# STM32L476 register map
File version: 1.0
CPU: CM4 r0p1, little endian, MPU, FPU, 4 interrupt priority bits
Registers are 32-bit, read-write, reset 0x0 unless marked. A register's access mark holds for its fields unless they carry their own. Offsets are from the block's base; [hi:lo] are bit positions; {n}, {i} and the like mark numbered series.

## NVIC — Nested Vectored Interrupt Controller
Base 0xE000E100
{0x0+4i} ISER{i} (i=0..2) — Interrupt Set-Enable Register
  [31:0] SETENA
{0x80+4i} ICER{i} (i=0..2) — Interrupt Clear-Enable Register
  [31:0] CLRENA
{0x100+4i} ISPR{i} (i=0..2) — Interrupt Set-Pending Register
  [31:0] SETPEND
{0x180+4i} ICPR{i} (i=0..2) — Interrupt Clear-Pending Register
  [31:0] CLRPEND
{0x200+4i} IABR{i} ro (i=0..2) — Interrupt Active Bit Register
  [31:0] ACTIVE
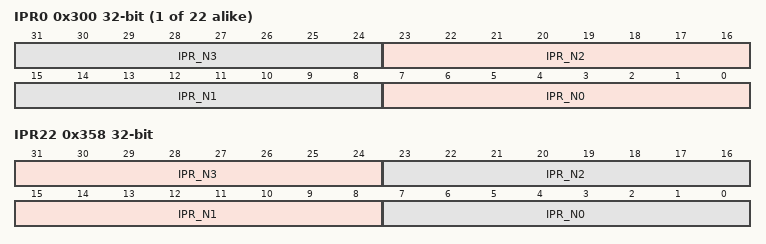
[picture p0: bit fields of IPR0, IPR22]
{0x300+4i} IPR{i} (i=0..21) — Interrupt Priority Register
  [8n+7:8n] IPR_N{n} (n=0..3)
0x358 IPR22 — Interrupt Priority Register
  [31:24] IPR_N3
  [23:16] IPR_N2 — IPR_N0
  [15:8] IPR_N1
  [7:0] IPR_N0

## CRS — Clock recovery system
Base 0x40006000
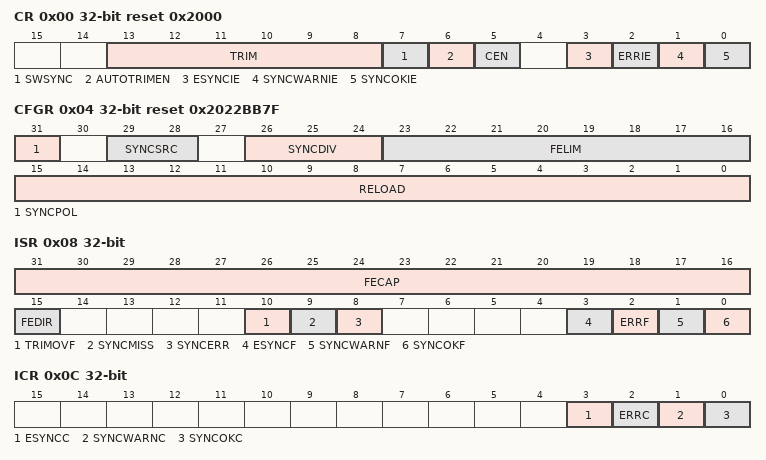
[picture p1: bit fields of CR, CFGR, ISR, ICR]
0x00 CR reset 0x2000 — control register
  [13:8] TRIM — HSI48 oscillator smooth trimming
  [7] SWSYNC — Generate software SYNC event
  [6] AUTOTRIMEN — Automatic trimming enable
  [5] CEN — Frequency error counter enable
  [3] ESYNCIE — Expected SYNC interrupt enable
  [2] ERRIE — Synchronization or trimming error interrupt enable
  [1] SYNCWARNIE — SYNC warning interrupt enable
  [0] SYNCOKIE — SYNC event OK interrupt enable
0x04 CFGR reset 0x2022BB7F — configuration register
  [31] SYNCPOL — SYNC polarity selection
  [29:28] SYNCSRC — SYNC signal source selection
  [26:24] SYNCDIV — SYNC divider
  [23:16] FELIM — Frequency error limit
  [15:0] RELOAD — Counter reload value
0x08 ISR ro — interrupt and status register
  [31:16] FECAP — Frequency error capture
  [15] FEDIR — Frequency error direction
  [10] TRIMOVF — Trimming overflow or underflow
  [9] SYNCMISS — SYNC missed
  [8] SYNCERR — SYNC error
  [3] ESYNCF — Expected SYNC flag
  [2] ERRF — Error flag
  [1] SYNCWARNF — SYNC warning flag
  [0] SYNCOKF — SYNC event OK flag
0x0C ICR — interrupt flag clear register
  [3] ESYNCC — Expected SYNC clear flag
  [2] ERRC — Error clear flag
  [1] SYNCWARNC — SYNC warning clear flag
  [0] SYNCOKC — SYNC event OK clear flag

## DCMI — Digital camera interface
Base 0x50050000
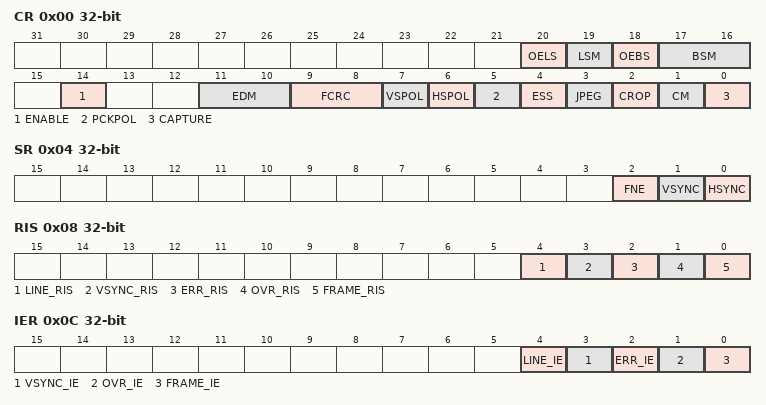
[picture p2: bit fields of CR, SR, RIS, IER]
0x00 CR — control register 1
  [20] OELS — Odd/Even Line Select (Line Select Start)
  [19] LSM — Line Select mode
  [18] OEBS — Odd/Even Byte Select (Byte Select Start)
  [17:16] BSM — Byte Select mode
  [14] ENABLE — DCMI enable
  [11:10] EDM — Extended data mode
  [9:8] FCRC — Frame capture rate control
  [7] VSPOL — Vertical synchronization polarity
  [6] HSPOL — Horizontal synchronization polarity
  [5] PCKPOL — Pixel clock polarity
  [4] ESS — Embedded synchronization select
  [3] JPEG — JPEG format
  [2] CROP — Crop feature
  [1] CM — Capture mode
  [0] CAPTURE — Capture enable
0x04 SR ro — status register
  [2] FNE — FIFO not empty
  [1] VSYNC
  [0] HSYNC
0x08 RIS ro — raw interrupt status register
  [4] LINE_RIS — Line raw interrupt status
  [3] VSYNC_RIS — VSYNC raw interrupt status
  [2] ERR_RIS — Synchronization error raw interrupt status
  [1] OVR_RIS — Overrun raw interrupt status
  [0] FRAME_RIS — Capture complete raw interrupt status
0x0C IER — interrupt enable register
  [4] LINE_IE — Line interrupt enable
  [3] VSYNC_IE — VSYNC interrupt enable
  [2] ERR_IE — Synchronization error interrupt enable
  [1] OVR_IE — Overrun interrupt enable
  [0] FRAME_IE — Capture complete interrupt enable
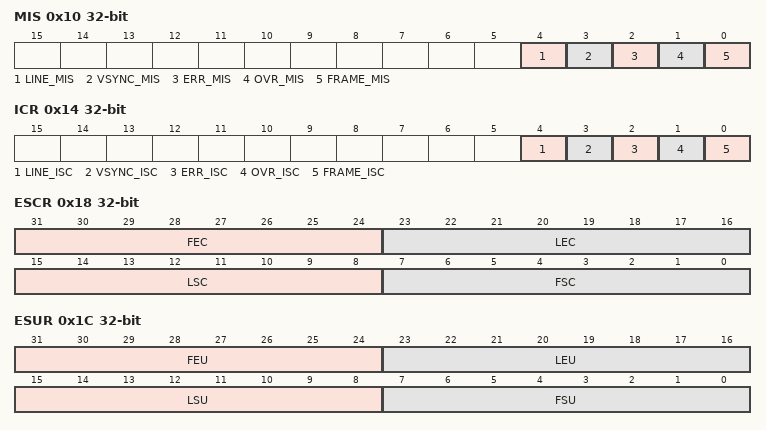
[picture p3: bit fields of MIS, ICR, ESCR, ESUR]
0x10 MIS ro — masked interrupt status register
  [4] LINE_MIS — Line masked interrupt status
  [3] VSYNC_MIS — VSYNC masked interrupt status
  [2] ERR_MIS — Synchronization error masked interrupt status
  [1] OVR_MIS — Overrun masked interrupt status
  [0] FRAME_MIS — Capture complete masked interrupt status
0x14 ICR wo — interrupt clear register
  [4] LINE_ISC — line interrupt status clear
  [3] VSYNC_ISC — Vertical synch interrupt status clear
  [2] ERR_ISC — Synchronization error interrupt status clear
  [1] OVR_ISC — Overrun interrupt status clear
  [0] FRAME_ISC — Capture complete interrupt status clear
0x18 ESCR — embedded synchronization code register
  [31:24] FEC — Frame end delimiter code
  [23:16] LEC — Line end delimiter code
  [15:8] LSC — Line start delimiter code
  [7:0] FSC — Frame start delimiter code
0x1C ESUR — embedded synchronization unmask register
  [31:24] FEU — Frame end delimiter unmask
  [23:16] LEU — Line end delimiter unmask
  [15:8] LSU — Line start delimiter unmask
  [7:0] FSU — Frame start delimiter unmask
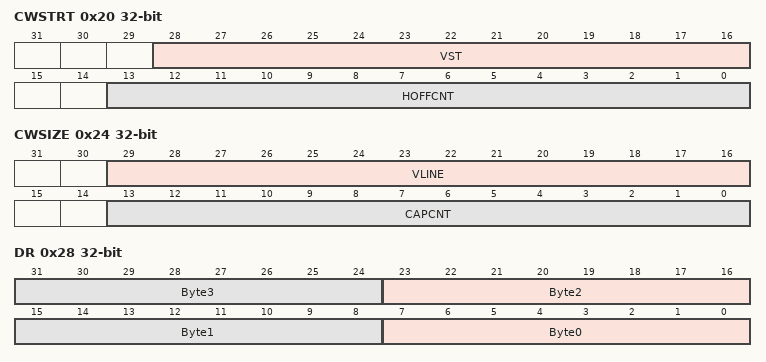
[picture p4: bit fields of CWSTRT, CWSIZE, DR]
0x20 CWSTRT — crop window start
  [28:16] VST — Vertical start line count
  [13:0] HOFFCNT — Horizontal offset count
0x24 CWSIZE — crop window size
  [29:16] VLINE — Vertical line count
  [13:0] CAPCNT — Capture count
0x28 DR ro — data register
  [8n+7:8n] Byte{n} (n=0..3) — Data byte {n}

## FPU — Floting point unit
Base 0xE000EF34
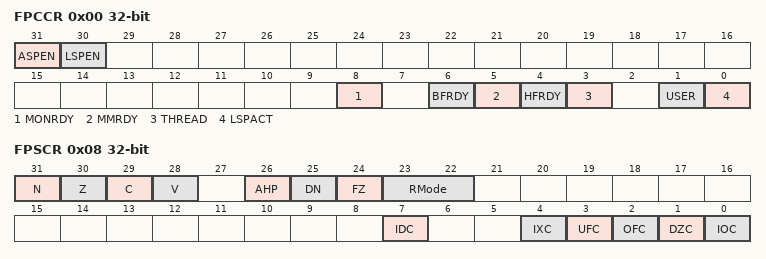
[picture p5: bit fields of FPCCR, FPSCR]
0x00 FPCCR — Floating-point context control register
  [31] ASPEN, [30] LSPEN, [8] MONRDY, [6] BFRDY, [5] MMRDY, [4] HFRDY, [3] THREAD, [1] USER, [0] LSPACT
0x04 FPCAR — Floating-point context address register
  [31:3] ADDRESS — Location of unpopulated floating-point
0x08 FPSCR — Floating-point status control register
  [31] N — Negative condition code flag
  [30] Z — Zero condition code flag
  [29] C — Carry condition code flag
  [28] V — Overflow condition code flag
  [26] AHP — Alternative half-precision control bit
  [25] DN — Default NaN mode control bit
  [24] FZ — Flush-to-zero mode control bit:
  [23:22] RMode — Rounding Mode control field
  [7] IDC — Input denormal cumulative exception bit.
  [4] IXC — Inexact cumulative exception bit
  [3] UFC — Underflow cumulative exception bit
  [2] OFC — Overflow cumulative exception bit
  [1] DZC — Division by zero cumulative exception bit.
  [0] IOC — Invalid operation cumulative exception bit

## MPU — Memory protection unit
Base 0xE000ED90
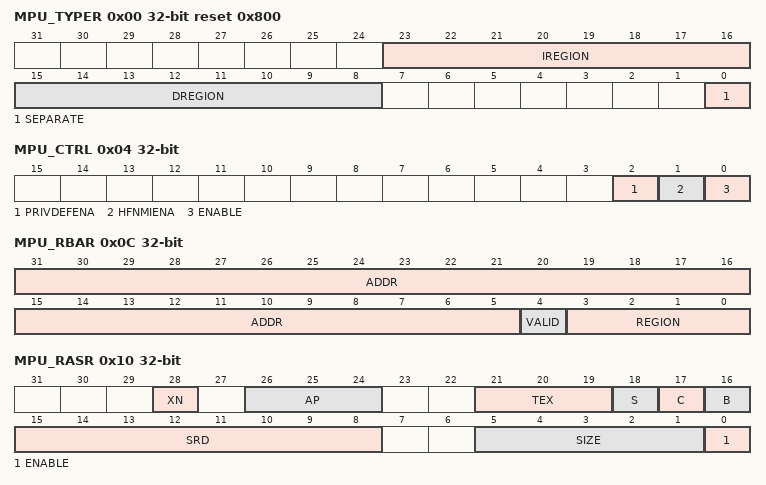
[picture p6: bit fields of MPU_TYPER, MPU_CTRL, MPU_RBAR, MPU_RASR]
0x00 MPU_TYPER ro reset 0x800 — MPU type register
  [23:16] IREGION — Number of MPU instruction regions
  [15:8] DREGION — Number of MPU data regions
  [0] SEPARATE — Separate flag
0x04 MPU_CTRL ro — MPU control register
  [2] PRIVDEFENA — Enable priviliged software access to default memory map
  [1] HFNMIENA — Enables the operation of MPU during hard fault
  [0] ENABLE — Enables the MPU
0x08 MPU_RNR — MPU region number register
  [7:0] REGION — MPU region
0x0C MPU_RBAR — MPU region base address register
  [31:5] ADDR — Region base address field
  [4] VALID — MPU region number valid
  [3:0] REGION — MPU region field
0x10 MPU_RASR — MPU region attribute and size register
  [28] XN — Instruction access disable bit
  [26:24] AP — Access permission
  [21:19] TEX — memory attribute
  [18] S — Shareable memory attribute
  [17] C — memory attribute
  [16] B — memory attribute
  [15:8] SRD — Subregion disable bits
  [5:1] SIZE — Size of the MPU protection region
  [0] ENABLE — Region enable bit.

## STK — SysTick timer
Base 0xE000E010
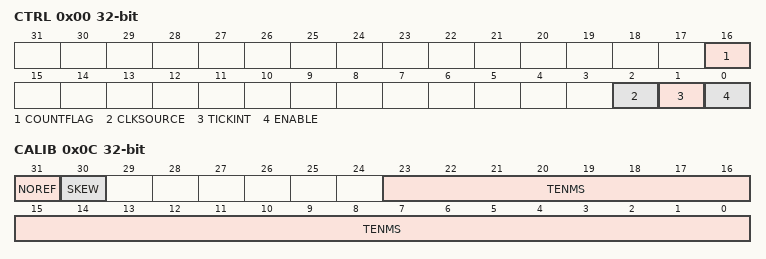
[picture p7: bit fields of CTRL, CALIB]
0x00 CTRL — SysTick control and status register
  [16] COUNTFLAG
  [2] CLKSOURCE — Clock source selection
  [1] TICKINT — SysTick exception request enable
  [0] ENABLE — Counter enable
0x04 LOAD — SysTick reload value register
  [23:0] RELOAD — RELOAD value
0x08 VAL — SysTick current value register
  [23:0] CURRENT — Current counter value
0x0C CALIB — SysTick calibration value register
  [31] NOREF — NOREF flag. Reads as zero
  [30] SKEW — SKEW flag: Indicates whether the TENMS value is exact
  [23:0] TENMS — Calibration value

## NVIC_STIR — Nested vectored interrupt controller
Base 0xE000EF00
0x00 STIR — Software trigger interrupt register
  [8:0] INTID — Software generated interrupt ID

## FPU_CPACR — Floating point unit CPACR
Base 0xE000ED88
0x00 CPACR — Coprocessor access control register
  [23:20] CP

## SCB_ACTRL — System control block ACTLR
Base 0xE000E008
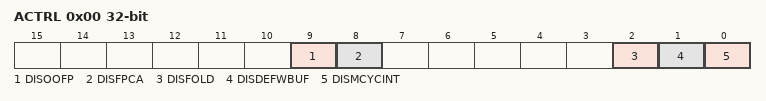
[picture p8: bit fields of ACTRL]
0x00 ACTRL — Auxiliary control register
  [9] DISOOFP, [8] DISFPCA, [2] DISFOLD, [1] DISDEFWBUF, [0] DISMCYCINT
